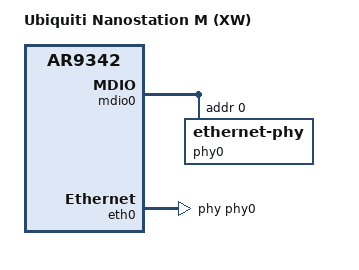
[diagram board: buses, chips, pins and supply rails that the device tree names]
// SPDX-License-Identifier: GPL-2.0-or-later OR MIT

#include "ar9342_ubnt_xw.dtsi"

/ {
	compatible = "ubnt,nanostation-m-xw", "ubnt,xw", "qca,ar9342";
	model = "Ubiquiti Nanostation M (XW)";
};

&mdio0 {
	status = "okay";

	phy4-mii-enable;
	phy-mask = <0x23>;

	phy0: ethernet-phy@0 {
		reg = <0>;
		phy-mode = "mii";
	};
};

&eth0 {
	status = "okay";

	phy-handle = <&phy0>;

	gmac-config {
		device = <&gmac>;
		mii-gmac0 = <1>;
		mii-gmac0-slave = <1>;
	};
};
